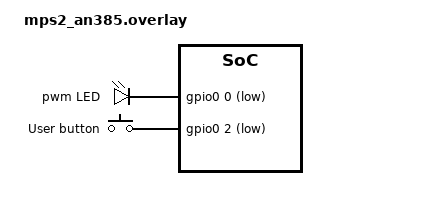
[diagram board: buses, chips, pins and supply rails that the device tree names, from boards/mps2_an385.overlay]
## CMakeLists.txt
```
# meu_app/CMakeLists.txt
cmake_minimum_required(VERSION 3.20.1)
set(ZEPHYR_EXTRA_MODULES "${CMAKE_CURRENT_SOURCE_DIR}/camera_service/")
find_package(Zephyr REQUIRED HINTS $ENV{ZEPHYR_BASE})
zephyr_include_directories(.)
project(radar_app)

target_sources(app PRIVATE src/main.c)
```

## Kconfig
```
menu "Zephyr"
    
config RADAR_SENSOR_DISTANCE_MM
    int "distance between sensors in mm"
    default 10000

config RADAR_SPEED_LIMIT_LIGHT_KMH
    int "Limite de velocidade para veículos leves (km/h)."
    default 100

config RADAR_SPEED_LIMIT_HEAVY_KMH
    int "Limite de velocidade para veículos pesados (km/h)."
    default 80

config RADAR_WARNING_THRESHOLD_PERCENT
    int "Percentual do limite que ativa o display amarelo"
    default 90

config RADAR_CAMERA_FAILURE_RATE_PERCENT
    int "Porcentagem de chance da câmera simular uma falha (0-100)."
    default 10

    
source "Kconfig.zephyr"
endmenu
```

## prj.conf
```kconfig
CONFIG_GPIO_EMUL=y
CONFIG_PWM=y
CONFIG_LOG=y
CONFIG_LOG_MODE_IMMEDIATE=y
CONFIG_UART_CONSOLE=y
CONFIG_GPIO=y
CONFIG_ENTROPY_GENERATOR=y
CONFIG_TEST_RANDOM_GENERATOR=y
CONFIG_ZBUS=y
CONFIG_ZBUS_MSG_SUBSCRIBER=y
CONFIG_TEST_RANDOM_GENERATOR=y
CONFIG_QEMU_ICOUNT=n
```

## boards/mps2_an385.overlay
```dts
#include <zephyr/dt-bindings/gpio/gpio.h>

/ {
    aliases {
        led0 = &led0;
		buttom0 = &button0;
    };

    leds {
		compatible = "gpio-leds";

		led0: led0 {
			gpios = <&gpio0 0 GPIO_ACTIVE_LOW>;
			label = "pwm LED";
		};
	};

	gpio_keys {
        compatible = "gpio-keys";
        button0: button_0 {
            label = "User button";
            gpios = <&gpio0 2 (GPIO_PULL_UP | GPIO_ACTIVE_LOW)>;
        };
    };
};
```

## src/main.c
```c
#include <zephyr/kernel.h>
#include <zephyr/drivers/gpio.h>
#include <zephyr/zbus/zbus.h>
#include <zephyr/drivers/uart.h>
#include "camera_service.h"
#include "validate_plate.h"
#include "display_thread.c"
#include "speed_sensor_thread.c"

/*define the global thread values*/
#define THREAD_STACK_SIZE 1024
#define THREAD_PRIORITY 3

/*defines the zbus for the camera acess*/
ZBUS_MSG_SUBSCRIBER_DEFINE(msub_camera_evt);
ZBUS_CHAN_ADD_OBS(chan_camera_evt, msub_camera_evt, 3);

/*defines the gpio dt for inputs and device to simulate inputs*/
static const struct gpio_dt_spec mag_1 = GPIO_DT_SPEC_GET(DT_ALIAS(mag_sensor_1), gpios);
static const struct gpio_dt_spec mag_2 = GPIO_DT_SPEC_GET(DT_ALIAS(mag_sensor_2), gpios);
static const struct device* const console_dev = DEVICE_DT_GET(DT_CHOSEN(zephyr_console));

/*thread only for manual test via keyboard
    press '1' to simulate the magnetic sensor 1
    press '2' to simulate the magnetic sensor 2 
*/
void manual_tests_thread_start(void *arg_1, void *arg_2, void *arg_3){
    static struct device dummy;
    static struct gpio_callback dummy_cb;

    unsigned char c;

    while (1) {
        k_usleep(10);
        if (uart_poll_in(console_dev, &c) == -1) c = '0';

		if (c == '1') {
            mag_1_callback_func(&dummy, &dummy_cb, 1 << 6);
        }
        else if (c == '2')  {
            mag_2_callback_func(&dummy, &dummy_cb, 1 << 6);
        }
	}
}

/*main thread*/
int main(void)
{
    /*check if the mag sensors are ready*/
    if (!gpio_is_ready_dt(&mag_1) || !gpio_is_ready_dt(&mag_2)) {
        printk("mag sensors not ready\r\n");
        return -1;
    }
    
    /*configures the mag sensors*/
    gpio_pin_configure_dt(&mag_1, GPIO_INPUT | GPIO_INT_EDGE_TO_ACTIVE);
    gpio_init_callback(&mag_1_cb_data, mag_1_callback_func, BIT(mag_1.pin));
    gpio_add_callback(mag_1.port, &mag_1_cb_data);
    gpio_pin_interrupt_configure_dt(&mag_1, GPIO_INT_EDGE_TO_ACTIVE);

    gpio_pin_configure_dt(&mag_2, GPIO_INPUT | GPIO_INT_EDGE_TO_ACTIVE);
    gpio_init_callback(&mag_2_cb_data, mag_2_callback_func, BIT(mag_2.pin));
    gpio_add_callback(mag_2.port, &mag_2_cb_data);
    gpio_pin_interrupt_configure_dt(&mag_2, GPIO_INT_EDGE_TO_ACTIVE);

    int ret;
    const struct zbus_channel *chan;
    speed_sensor_data speed_sensor;
    display_data display;

    while(1){
        k_msleep(500);

        /*wait for the speed sensor produce some data*/
        ret = k_msgq_get(&speed_sensor_msgq, &speed_sensor, K_FOREVER);
        if (ret != 0) {
            printk("Could not get msgq data. Error: %d\n", ret);
            continue;
        }

        /*if the speed sensor produces a a valid data, ask the camera api for the plate*/
        printk("%d, %d\r\n", speed_sensor.axis_count, speed_sensor.speed);
		ret = camera_api_capture(K_FOREVER);
		if (ret) {
			printk("Could not init capture. Error: %d\n", ret);
			continue;
		}

		struct msg_camera_evt rsp;

		ret = zbus_sub_wait_msg(&msub_camera_evt, &chan, &rsp, K_FOREVER);
		if (ret) {
			printk("ERROR: %d\n", ret);
			continue;
		}

        /*if the camera api returns something, check if its a plate*/
		if (rsp.type == MSG_CAMERA_EVT_TYPE_ERROR) {
			printk("Camera service unavailable. Error code %d\n", rsp.error_code);
            strcpy(display.plate, "INVALID");
		} else if (rsp.type == MSG_CAMERA_EVT_TYPE_DATA) {
            /*check if the plate is a valid plate*/
            memcpy(display.plate, rsp.captured_data->plate, strlen(rsp.captured_data->plate) + 1);
            if (!validate_mercosul_plate(display.plate)) strcpy(display.plate, "INVALID");
		}

        /*put the data on a struct and send to display msgq*/
        display.speed = speed_sensor.speed;
        display.axis_count = speed_sensor.axis_count;
        
        k_msgq_put(&display_msgq, &display, K_NO_WAIT);
    }
	
    return 0;
}

K_THREAD_DEFINE(speed_sensor_thread, THREAD_STACK_SIZE, speed_sensor_thread_start, 
                    NULL, NULL, NULL, THREAD_PRIORITY, 0, 0);
K_THREAD_DEFINE(manual_tests_thread, THREAD_STACK_SIZE, manual_tests_thread_start, 
                    NULL, NULL, NULL, 0, 0, 0);
K_THREAD_DEFINE(display_thread, THREAD_STACK_SIZE, display_thread_start, 
                    NULL, NULL, NULL, THREAD_PRIORITY, 0, 0);
        
        
```

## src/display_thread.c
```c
#include <zephyr/kernel.h>

/*data utilized by the display*/
typedef struct {
    uint16_t speed;
    uint8_t axis_count;
    char plate[10];
}display_data;
K_MSGQ_DEFINE(display_msgq, sizeof(display_data), 8, 4);

enum {
    RED = 0,
    YELLOW,
    GREEN
}Colors;

void display_thread_start(void *arg_1, void *arg_2, void *arg_3){
    display_data display;
    int ret;
    int color;

    while(1){
        k_msleep(10);
        /*wait to get some message on msgq*/
        ret = k_msgq_get(&display_msgq, &display, K_FOREVER);

        if(ret != 0){
            printk("Error on display msgq: %d\n\r", ret);
        }

        /*check the speed to assing the correct color on the display*/
        color = GREEN;
        if (display.axis_count <= 2){
            if (display.speed > CONFIG_RADAR_SPEED_LIMIT_LIGHT_KMH){
                color = RED;
            }
            else if (display.speed > ((CONFIG_RADAR_SPEED_LIMIT_LIGHT_KMH * CONFIG_RADAR_WARNING_THRESHOLD_PERCENT)
                                        /100)){
                color = YELLOW;
            }
        }
        else{
            if (display.speed > CONFIG_RADAR_SPEED_LIMIT_HEAVY_KMH){
                color = RED;
            }
            else if (display.speed > ((CONFIG_RADAR_SPEED_LIMIT_HEAVY_KMH * 100)
                                        /CONFIG_RADAR_WARNING_THRESHOLD_PERCENT)){
                color = YELLOW;
            }
        }
        char *terminal_color_code;
        if (color == RED) terminal_color_code = "\x1b[91m";
        if (color == YELLOW) terminal_color_code = "\x1b[33m";
        if (color == GREEN) terminal_color_code = "\x1b[32m";

        /*print the display with correct color*/
        printk("%s╔═══════════════════════╗\x1b[0m\n", terminal_color_code);
        printk("%s║   SPEED: %d\t\t║\x1b[0m\n", terminal_color_code, display.speed);
        printk("%s║   AXIS: %d\t\t║\x1b[0m\n", terminal_color_code, display.axis_count);
        printk("%s║   PLATE: %s\t║\x1b[0m\n", terminal_color_code, display.plate);
        printk("%s╚═══════════════════════╝\x1b[0m\n", terminal_color_code);
        
        printk("speed: %d, axix count: %d, plate: %s\n", display.speed, display.axis_count, display.plate);
    }
}
```

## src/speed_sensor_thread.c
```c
#include <zephyr/kernel.h>
#include <zephyr/drivers/gpio.h>

/*defines the gpio callback*/
static struct gpio_callback mag_1_cb_data;
static struct gpio_callback mag_2_cb_data;

/*defines the semaphore*/
K_SEM_DEFINE(speed_sem, 0, 1);   

/*data utilized by the sensor mensage queue*/
typedef struct {
    uint16_t speed;
    uint8_t axis_count;
} speed_sensor_data;
K_MSGQ_DEFINE(speed_sensor_msgq, sizeof(speed_sensor_data), 16, 4);

/*structure utilized as a data storage to the state machine*/
struct {
    uint8_t axis_count;
    uint16_t speed;
    int64_t last_sleed_measure_time;
}speed_measure = {0};

void reset_speed_sensor(){
    speed_measure.speed = 0;
    speed_measure.axis_count = 0;
    speed_measure.last_sleed_measure_time = 0;
}

void mag_1_callback_func(const struct device *dev, struct gpio_callback *cb, uint32_t pins)
{
    /*starts the state machine and count axis*/
    if (speed_measure.axis_count == 0)
        speed_measure.last_sleed_measure_time = k_uptime_get();
    speed_measure.axis_count += 1;
}

void mag_2_callback_func(const struct device *dev, struct gpio_callback *cb, uint32_t pins)
{
    /*update the state machine calculating the speed and resets the wait time*/
    if (speed_measure.speed == 0 && speed_measure.axis_count >= 1){
        speed_measure.speed = CONFIG_RADAR_SENSOR_DISTANCE_MM/(k_uptime_get() - speed_measure.last_sleed_measure_time)* 3.6f;
        /*give a green sim to the sensor thread*/
        k_sem_give(&speed_sem);
    }
    else if(speed_measure.speed != 0){
        speed_measure.last_sleed_measure_time = k_uptime_get();
    }
}

void speed_sensor_thread_start(void *arg_1, void *arg_2, void *arg_3)
{
    while(1){
        /*stop the thread waiting for a green sem*/
        if (speed_measure.axis_count == 0){
            k_sem_take(&speed_sem, K_FOREVER);
        }

        /*check if readed speed = 0*/
        if (speed_measure.speed == 0){
            if (k_uptime_get() - speed_measure.last_sleed_measure_time > 1000) {
                printk("speed not readed\n\r");
                reset_speed_sensor();
            }
        }
        /*wait a timer defined by (distance * 8 /speed) to make sure the entire veichle has passed
        and there is no other one*/
        else{
            if (k_uptime_get() - speed_measure.last_sleed_measure_time > (CONFIG_RADAR_SENSOR_DISTANCE_MM * 8) / speed_measure.speed) {
                speed_sensor_data speed_sensor = {.axis_count = speed_measure.axis_count, 
                                                  .speed = speed_measure.speed};

                k_msgq_put(&speed_sensor_msgq, &speed_sensor, K_NO_WAIT);
                reset_speed_sensor();
            }
        }
    }
}
```

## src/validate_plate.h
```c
#include <string.h>

bool is_num(char c){
    return (c >= '0' && c <= '9') ? true : false;
}

bool is_letter(char c){
    return ((c >= 'a' && c <= 'z') || (c >= 'A' && c <= 'Z')) ? true : false;
}

/*
brasil: ABC1D23, or ABC12D3
argentina: AB 123 CD
paraguai: ABCD 123 or 123 ABCD
uruguai: ABC 1234
venezuela: AB 123 CD
bolivia: AB 12345
*/

bool validate_argentina(char *plate){
    if(strlen(plate) > 9) return false;

    if (is_letter(plate[0])                         && 
        is_letter(plate[1])                         &&
        plate[2] == ' '                             &&
        is_num(plate[3])                            &&
        is_num(plate[4])                            &&
        is_num(plate[5])                            &&
        plate[6] == ' '                             &&
        is_letter(plate[7])                         &&
        is_letter(plate[8])) 
                            return true;
    else return false;
}
bool validate_brazil(char *plate){
    if(strlen(plate) > 7) return false;

    if (is_letter(plate[0])                         && 
        is_letter(plate[1])                         &&
        is_letter(plate[2])                         &&
        is_num(plate[3])                            &&
        (is_letter(plate[4]) || is_num(plate[4]))   &&
        is_num(plate[5])                            &&
        is_num(plate[6])) 
                        return true;
    else return false;
}

bool validate_paraguay(char *plate){
    if(strlen(plate) > 8) return false;

    if ((is_letter(plate[0]) || is_num(plate[0]))       && 
        (is_letter(plate[1]) || is_num(plate[1]))       &&
        (is_letter(plate[2]) || is_num(plate[2]))       &&
        (is_letter(plate[3]) || plate[3] == ' ')        &&
        (plate[4] == ' '     || is_letter(plate[4]))    &&
        (is_letter(plate[5]) || is_num(plate[5]))       &&
        (is_letter(plate[6]) || is_num(plate[6]))       &&
        (is_letter(plate[7]) || is_num(plate[7]))) 
                                                    return true;

    else return false;
}
//uruguai: ABC 1234

bool validate_uruguai(char *plate){
    if(strlen(plate) > 8) return false;

    if (is_letter(plate[0]) && 
        is_letter(plate[1]) &&
        is_letter(plate[2]) &&
        plate[3] == ' '     &&
        is_num(plate[4])    &&
        is_num(plate[5])    &&
        is_num(plate[6])    &&
        is_num(plate[7])) 
                        return true;
    else return false;

}

bool validate_venezuela(char *plate){
    return validate_argentina(plate);
}

bool validate_bolivia(char *plate){
    if(strlen(plate) > 8) return false;

    if (is_letter(plate[0]) && 
        is_letter(plate[1]) &&
        plate[2] == ' '     &&
        is_num(plate[3])    &&
        is_num(plate[4])    &&    
        is_num(plate[5])    &&
        is_num(plate[6])    &&
        is_num(plate[7])
    ) return true;

    else return false;

}
bool validate_mercosul_plate(char *plate){
    if (
        validate_argentina(plate)   ||
        validate_brazil(plate)      ||
        validate_paraguay(plate)    ||
        validate_venezuela(plate)   ||
        validate_uruguai(plate)     ||
        validate_paraguay(plate)    ||
        validate_paraguay(plate)
    ) return true;

    else return false;
}
```
